# cslr_vcp2_001 register map
Vendor: Texas Instruments
Peripheral module from a debugger description file.
Registers are 32-bit, read-write, reset 0x0 unless marked. A register's access mark holds for its fields unless they carry their own. Offsets are as the file gives them; lines under a group give offsets from that group; [hi:lo] are bit positions; {n}, {i} and the like mark numbered series; 'fields as' and 'values as' point back to an identical list; <NAME> marks a mode.

## VCP2 — Viterbi Coprocessor 2
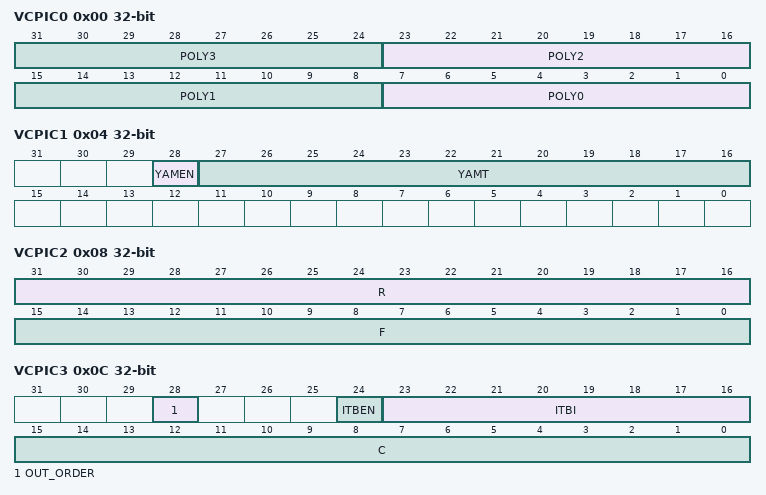
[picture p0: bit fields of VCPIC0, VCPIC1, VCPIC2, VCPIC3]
0x00 VCPIC0 — VCP Input Configuration Register 0
  [8n+7:8n] POLY{n} (n=0..3) — Polynomial generator G{n}
0x04 VCPIC1 — VCP Input Configuration Register 1
  [28] YAMEN — Yamamoto algorithm enable bit
    0=DISABLE (Yamamoto algorithm is disabled); 1=ENABLE (Yamamoto algorithm is enabled)
  [27:16] YAMT — Yamamoto threshold value bits
0x08 VCPIC2 — VCP Input Configuration Register 2
  [31:16] R — Reliability length bits
  [15:0] F — Frame length bits
0x0C VCPIC3 — VCP Input Configuration Register 3
  [28] OUT_ORDER — The order of VCP output for decoded data
    0=0to31 (The order of VCP output for decoded data); 1=31to0
  [24] ITBEN — Traceback state index enable/disable
    0=DISABLED (Traceback state index enable/disable); 1=ENABLED
  [23:16] ITBI — Traceback state index. The index of the starting state for the traceback unit
  [15:0] C — Convergence distance bits
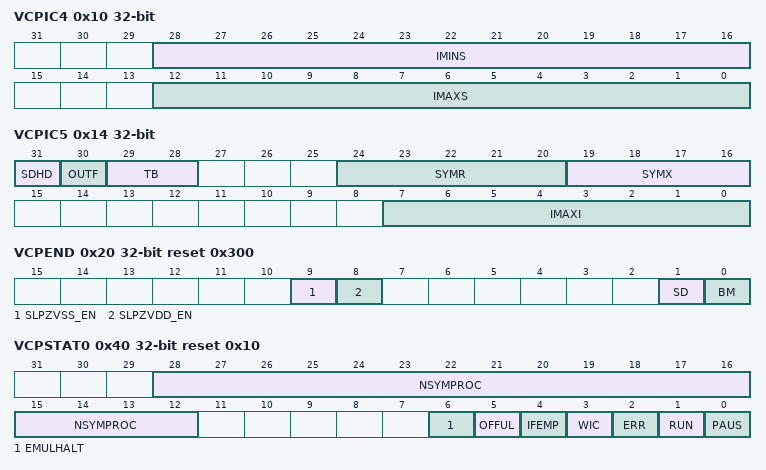
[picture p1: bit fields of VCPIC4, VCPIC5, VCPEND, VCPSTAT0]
0x10 VCPIC4 — VCP Input Configuration Register 4
  [28:16] IMINS — Minimum initial state metric value bits. 13-bits
  [12:0] IMAXS — Maximum initial state metric value bits. 13-bits
0x14 VCPIC5 — VCP Input Configuration Register 5
  [31] SDHD — Output decision type select bit
    0=HARD (Hard decisions); 1=SOFT (Soft decisions)
  [30] OUTF — Output parameters read flag bit
    0=NO (VCPREVT generated by VCP for output parameters read); 1=YES (VCPREVT is not generated by VCP for output parameters read)
  [29:28] TB — Traceback mode select bits
    0=NO (Not allowed); 1=TAIL (Tailed f less than or equal to Fmax); 2=CONV (Convergent no tail bits); 3=MIX (Mixed f greater than or equal to Fmax and tail bits are used)
  [24:20] SYMR — Output FIFO decision buffer length
  [19:16] SYMX — Input FIFO branch metrics buffer length
  [7:0] IMAXI — Maximum initial state metric value bits
0x18 VCPEXE — VCP Execution Register
  [3:0] COMMAND — VCP command select bits
    1=START (Start VCP,Normal mode); 2=HALTORPAUSE (Halt or Pause VCP in debug mode); 3=RESTART (Restart VCP and process one SW in debug mode); 4=RESTART (Restart VCP in debug mode); 5=STOP (Stop. Soft reset all VCP registers to their initial condition)
0x20 VCPEND reset 0x300 — VCP Endian Mode Register
  [9] SLPZVSS_EN — sleep mode selection bit
    0=DISABLE (disable sleep mode); 1=ENABLE (enable internal control of slpzvss)
  [8] SLPZVDD_EN — sleep mode selection bit
    0=DISABLE (disable sleep mode); 1=ENABLE (enable internal control of slpzvdd)
  [1] SD — Soft-decisions memory format select bit
    0=32BIT (32bit word packed); 1=NATIVE (Native format 8 bits)
  [0] BM — Branch metrics memory format select bit
    0=32BIT (32bit word packed); 1=NATIVE (Native format 8 bits)
0x40 VCPSTAT0 access per field reset 0x10 — VCP Status Register 0
  [28:12] NSYMPROC ro — Number of symbols processed bits
  [6] EMULHALT ro — Emulation halt status bit
    0=NO (Not halt due to emulation); 1=YES (Halt due to emulation)
  [5] OFFUL ro — Output FIFO buffer full status bit
    0=NO (Output FIFO buffer is not full); 1=YES (Output FIFO buffer is full)
  [4] IFEMP ro — Input FIFO buffer empty status bit
    0=NO (Input FIFO buffer is not empty); 1=YES (Input FIFO buffer is empty)
  [3] WIC ro — Waiting for input configuration bit
    0=NO (Not waiting for input configuration words); 1=YES (Waiting for input configuration words)
  [2] ERR ro — VCP error status bit
    0=NO (No error); 1=YES (VCP paused due to error)
  [1] RUN ro — VCP running status bit
    0=NO (VCP is not running); 1=YES (VCP is running)
  [0] PAUS ro — VCP pause status bit
    0=NO (VCP is not paused); 1=YES (VCP is paused)
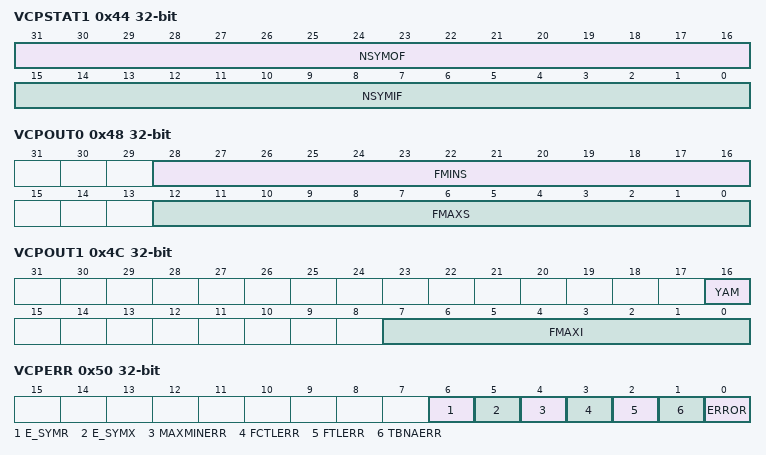
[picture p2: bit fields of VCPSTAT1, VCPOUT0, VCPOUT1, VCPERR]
0x44 VCPSTAT1 ro — VCP Status Register 1
  [31:16] NSYMOF — Number of symbols in the output FIFO buffer
  [15:0] NSYMIF — Number of symbols in the branch metric input FIFO buffer
0x48 VCPOUT0 access per field — VCP Output Register 0
  [28:16] FMINS ro — Minimum initial state metric value for the final trellis stage
  [12:0] FMAXS rw — Maximum state metric value for the final trellis stage
0x4C VCPOUT1 access per field — VCP Output Register 1
  [16] YAM ro — Yamamoto bit result
    0=NO (Poor Quality); 1=YES (Good Quality)
  [7:0] FMAXI ro — State index for the state with the final maximum state metric
0x50 VCPERR access per field — VCP Error Register
  [all] fields
    0=NoError; 1=Error
  [6] E_SYMR ro — Error check bit for SYMR
  [5] E_SYMX ro — Error check bit for SYMX
  [4] MAXMINERR ro — Error check bit for Maxmin value
  [3] FCTLERR ro — Error check bit for (Reliablity length + Convergance distance)
  [2] FTLERR ro — Error check bit for frame length
  [1] TBNAERR ro — Error check bit for trace back mode
  [0] ERROR ro — Error checking for vcp input parameters
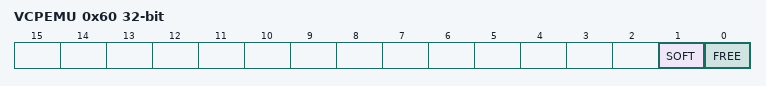
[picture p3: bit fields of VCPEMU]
0x60 VCPEMU — VCP Emulation Control Register
  [1] SOFT — VCP completes a frame of data before halting
  [0] FREE — Free run mode
